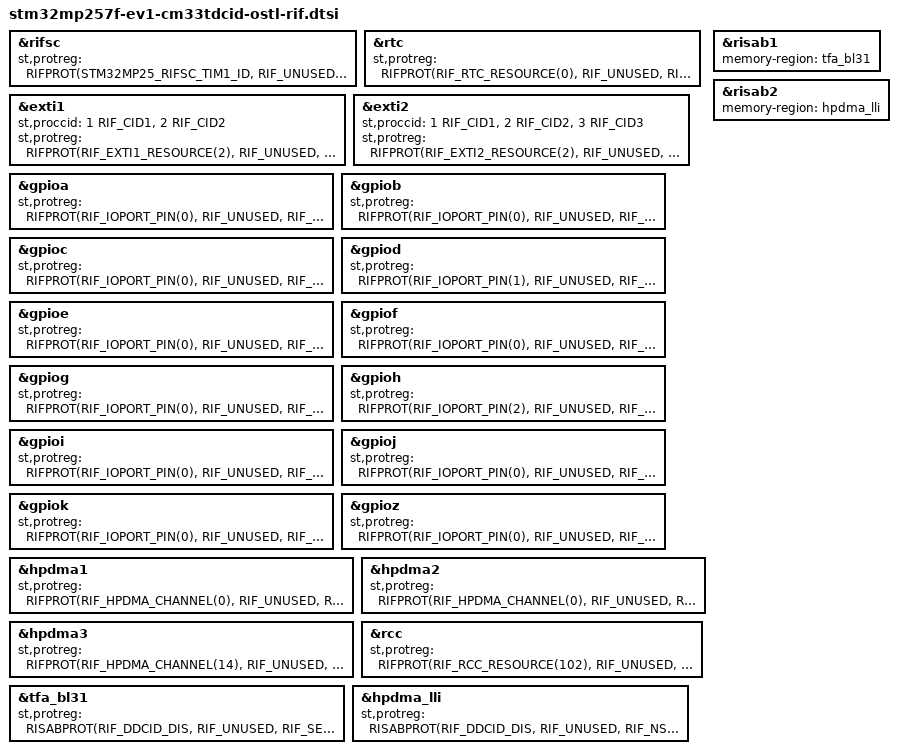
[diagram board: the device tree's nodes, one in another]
// SPDX-License-Identifier: (GPL-2.0-only OR BSD-3-Clause)
/*
 * Copyright (C) STMicroelectronics 2022 - All Rights Reserved
 * Author: Loic Pallardy loic.pallardy@foss.st.com for STMicroelectronics.
 */

/*
 * STM32MP25 RIF device tree configuration
 * Project : ostl-beta-m33td
 * Generated by XLmx tool version 2.2 - 11/21/2023 5:45:09 PM
 */

&rifsc {
	st,protreg = <
		RIFPROT(STM32MP25_RIFSC_TIM1_ID, RIF_UNUSED, RIF_UNLOCK, RIF_NSEC, RIF_NPRIV, RIF_CID1, RIF_SEM_DIS, RIF_CFEN)
		RIFPROT(STM32MP25_RIFSC_TIM3_ID, RIF_UNUSED, RIF_UNLOCK, RIF_NSEC, RIF_NPRIV, RIF_CID1, RIF_SEM_DIS, RIF_CFEN)
		RIFPROT(STM32MP25_RIFSC_TIM4_ID, RIF_UNUSED, RIF_UNLOCK, RIF_NSEC, RIF_NPRIV, RIF_CID1, RIF_SEM_DIS, RIF_CFEN)
		RIFPROT(STM32MP25_RIFSC_TIM5_ID, RIF_UNUSED, RIF_UNLOCK, RIF_NSEC, RIF_NPRIV, RIF_CID1, RIF_SEM_DIS, RIF_CFEN)
		RIFPROT(STM32MP25_RIFSC_TIM7_ID, RIF_UNUSED, RIF_UNLOCK, RIF_NSEC, RIF_NPRIV, RIF_CID1, RIF_SEM_DIS, RIF_CFEN)
		RIFPROT(STM32MP25_RIFSC_TIM8_ID, RIF_UNUSED, RIF_UNLOCK, RIF_NSEC, RIF_NPRIV, RIF_CID1, RIF_SEM_DIS, RIF_CFEN)
		RIFPROT(STM32MP25_RIFSC_TIM10_ID, RIF_UNUSED, RIF_UNLOCK, RIF_NSEC, RIF_NPRIV, RIF_CID1, RIF_SEM_DIS, RIF_CFEN)
		RIFPROT(STM32MP25_RIFSC_TIM11_ID, RIF_UNUSED, RIF_UNLOCK, RIF_NSEC, RIF_NPRIV, RIF_CID1, RIF_SEM_DIS, RIF_CFEN)
		RIFPROT(STM32MP25_RIFSC_TIM12_ID, RIF_UNUSED, RIF_UNLOCK, RIF_NSEC, RIF_NPRIV, RIF_CID1, RIF_SEM_DIS, RIF_CFEN)
		RIFPROT(STM32MP25_RIFSC_TIM13_ID, RIF_UNUSED, RIF_UNLOCK, RIF_NSEC, RIF_NPRIV, RIF_CID1, RIF_SEM_DIS, RIF_CFEN)
		RIFPROT(STM32MP25_RIFSC_TIM14_ID, RIF_UNUSED, RIF_UNLOCK, RIF_NSEC, RIF_NPRIV, RIF_CID1, RIF_SEM_DIS, RIF_CFEN)
		RIFPROT(STM32MP25_RIFSC_TIM15_ID, RIF_UNUSED, RIF_UNLOCK, RIF_NSEC, RIF_NPRIV, RIF_CID1, RIF_SEM_DIS, RIF_CFEN)
		RIFPROT(STM32MP25_RIFSC_TIM16_ID, RIF_UNUSED, RIF_UNLOCK, RIF_NSEC, RIF_NPRIV, RIF_CID1, RIF_SEM_DIS, RIF_CFEN)
		RIFPROT(STM32MP25_RIFSC_TIM17_ID, RIF_UNUSED, RIF_UNLOCK, RIF_NSEC, RIF_NPRIV, RIF_CID1, RIF_SEM_DIS, RIF_CFEN)
		RIFPROT(STM32MP25_RIFSC_TIM20_ID, RIF_UNUSED, RIF_UNLOCK, RIF_NSEC, RIF_NPRIV, RIF_CID1, RIF_SEM_DIS, RIF_CFEN)
		RIFPROT(STM32MP25_RIFSC_LPTIM1_ID, RIF_UNUSED, RIF_UNLOCK, RIF_NSEC, RIF_NPRIV, RIF_CID1, RIF_SEM_DIS, RIF_CFEN)
		RIFPROT(STM32MP25_RIFSC_LPTIM2_ID, RIF_UNUSED, RIF_UNLOCK, RIF_NSEC, RIF_NPRIV, RIF_CID1, RIF_SEM_DIS, RIF_CFEN)
		RIFPROT(STM32MP25_RIFSC_LPTIM3_ID, RIF_UNUSED, RIF_UNLOCK, RIF_NSEC, RIF_NPRIV, RIF_CID1, RIF_SEM_DIS, RIF_CFEN)
		RIFPROT(STM32MP25_RIFSC_LPTIM4_ID, RIF_UNUSED, RIF_UNLOCK, RIF_NSEC, RIF_NPRIV, RIF_CID1, RIF_SEM_DIS, RIF_CFEN)
		RIFPROT(STM32MP25_RIFSC_LPTIM5_ID, RIF_UNUSED, RIF_UNLOCK, RIF_NSEC, RIF_NPRIV, RIF_CID1, RIF_SEM_DIS, RIF_CFEN)
		RIFPROT(STM32MP25_RIFSC_SPI2_ID, RIF_UNUSED, RIF_UNLOCK, RIF_NSEC, RIF_NPRIV, RIF_CID1, RIF_SEM_DIS, RIF_CFEN)
		RIFPROT(STM32MP25_RIFSC_SPI3_ID, RIF_UNUSED, RIF_UNLOCK, RIF_NSEC, RIF_NPRIV, RIF_CID1, RIF_SEM_DIS, RIF_CFEN)
		RIFPROT(STM32MP25_RIFSC_SPI8_ID, RIF_UNUSED, RIF_UNLOCK, RIF_NSEC, RIF_NPRIV, RIF_CID1, RIF_SEM_DIS, RIF_CFEN)
		RIFPROT(STM32MP25_RIFSC_USART2_ID, RIF_UNUSED, RIF_UNLOCK, RIF_NSEC, RIF_NPRIV, RIF_CID1, RIF_SEM_DIS, RIF_CFEN)
		RIFPROT(STM32MP25_RIFSC_USART6_ID, RIF_UNUSED, RIF_UNLOCK, RIF_NSEC, RIF_NPRIV, RIF_CID1, RIF_SEM_DIS, RIF_CFEN)
		RIFPROT(STM32MP25_RIFSC_I2C2_ID, RIF_UNUSED, RIF_UNLOCK, RIF_NSEC, RIF_NPRIV, RIF_CID1, RIF_SEM_DIS, RIF_CFEN)
		RIFPROT(STM32MP25_RIFSC_I2C8_ID, RIF_UNUSED, RIF_UNLOCK, RIF_NSEC, RIF_NPRIV, RIF_CID1, RIF_SEM_DIS, RIF_CFEN)
		RIFPROT(STM32MP25_RIFSC_SAI2_ID, RIF_UNUSED, RIF_UNLOCK, RIF_NSEC, RIF_NPRIV, RIF_CID1, RIF_SEM_DIS, RIF_CFEN)
		RIFPROT(STM32MP25_RIFSC_MDF1_ID, RIF_UNUSED, RIF_UNLOCK, RIF_NSEC, RIF_NPRIV, RIF_CID1, RIF_SEM_DIS, RIF_CFEN)
		RIFPROT(STM32MP25_RIFSC_FDCAN_ID, RIF_UNUSED, RIF_UNLOCK, RIF_NSEC, RIF_NPRIV, RIF_CID1, RIF_SEM_DIS, RIF_CFEN)
		RIFPROT(STM32MP25_RIFSC_HDP_ID, RIF_UNUSED, RIF_UNLOCK, RIF_NSEC, RIF_PRIV, RIF_CID1, RIF_SEM_DIS, RIF_CFEN)
		RIFPROT(STM32MP25_RIFSC_ADC12_ID, RIF_UNUSED, RIF_UNLOCK, RIF_NSEC, RIF_NPRIV, RIF_CID1, RIF_SEM_DIS, RIF_CFEN)
		RIFPROT(STM32MP25_RIFSC_ETH1_ID, RIF_UNUSED, RIF_UNLOCK, RIF_NSEC, RIF_PRIV, RIF_CID1, RIF_SEM_DIS, RIF_CFEN)
		RIFPROT(STM32MP25_RIFSC_ETH2_ID, RIF_UNUSED, RIF_UNLOCK, RIF_NSEC, RIF_NPRIV, RIF_CID1, RIF_SEM_DIS, RIF_CFEN)
		RIFPROT(STM32MP25_RIFSC_ETHSW_DEIP_ID, RIF_UNUSED, RIF_UNLOCK, RIF_NSEC, RIF_PRIV, RIF_CID1, RIF_SEM_DIS, RIF_CFEN)
		RIFPROT(STM32MP25_RIFSC_ETHSW_ACM_MSGBUF_ID, RIF_UNUSED, RIF_UNLOCK, RIF_NSEC, RIF_NPRIV, RIF_CID1, RIF_SEM_DIS, RIF_CFEN)
		RIFPROT(STM32MP25_RIFSC_ETHSW_ACM_CFG_ID, RIF_UNUSED, RIF_UNLOCK, RIF_NSEC, RIF_PRIV, RIF_CID1, RIF_SEM_DIS, RIF_CFEN)
		RIFPROT(STM32MP25_RIFSC_USBH_ID, RIF_UNUSED, RIF_UNLOCK, RIF_NSEC, RIF_PRIV, RIF_CID1, RIF_SEM_DIS, RIF_CFEN)
		RIFPROT(STM32MP25_RIFSC_USB3DR_ID, RIF_UNUSED, RIF_UNLOCK, RIF_NSEC, RIF_PRIV, RIF_CID1, RIF_SEM_DIS, RIF_CFEN)
		RIFPROT(STM32MP25_RIFSC_COMBOPHY_ID, RIF_UNUSED, RIF_UNLOCK, RIF_NSEC, RIF_PRIV, RIF_CID1, RIF_SEM_DIS, RIF_CFEN)
		RIFPROT(STM32MP25_RIFSC_PCIE_ID, RIF_UNUSED, RIF_UNLOCK, RIF_NSEC, RIF_PRIV, RIF_CID1, RIF_SEM_DIS, RIF_CFEN)
		RIFPROT(STM32MP25_RIFSC_SDMMC1_ID, RIF_UNUSED, RIF_UNLOCK, RIF_NSEC, RIF_PRIV, RIF_CID1, RIF_SEM_DIS, RIF_CFEN)
		RIFPROT(STM32MP25_RIFSC_GPU_ID, RIF_UNUSED, RIF_UNLOCK, RIF_NSEC, RIF_PRIV, RIF_CID1, RIF_SEM_DIS, RIF_CFEN)
		RIFPROT(STM32MP25_RIFSC_LTDC_CMN_ID, RIF_UNUSED, RIF_UNLOCK, RIF_NSEC, RIF_PRIV, RIF_CID1, RIF_SEM_DIS, RIF_CFEN)
		RIFPROT(STM32MP25_RIFSC_LTDC_L0L1_ID, RIF_UNUSED, RIF_UNLOCK, RIF_NSEC, RIF_PRIV, RIF_CID1, RIF_SEM_DIS, RIF_CFEN)
		RIFPROT(STM32MP25_RIFSC_DSI_CMN_ID, RIF_UNUSED, RIF_UNLOCK, RIF_NSEC, RIF_PRIV, RIF_CID1, RIF_SEM_DIS, RIF_CFEN)
		RIFPROT(STM32MP25_RIFSC_DSI_TRIG_ID, RIF_UNUSED, RIF_UNLOCK, RIF_NSEC, RIF_PRIV, RIF_CID1, RIF_SEM_DIS, RIF_CFEN)
		RIFPROT(STM32MP25_RIFSC_DSI_RDFIFO_ID, RIF_UNUSED, RIF_UNLOCK, RIF_NSEC, RIF_PRIV, RIF_CID1, RIF_SEM_DIS, RIF_CFEN)
		RIFPROT(STM32MP25_RIFSC_LVDS_ID, RIF_UNUSED, RIF_UNLOCK, RIF_NSEC, RIF_PRIV, RIF_CID1, RIF_SEM_DIS, RIF_CFEN)
		RIFPROT(STM32MP25_RIFSC_CSI_ID, RIF_UNUSED, RIF_UNLOCK, RIF_NSEC, RIF_NPRIV, RIF_CID1, RIF_SEM_DIS, RIF_CFEN)
		RIFPROT(STM32MP25_RIFSC_DCMIPP_ID, RIF_UNUSED, RIF_UNLOCK, RIF_NSEC, RIF_NPRIV, RIF_CID1, RIF_SEM_DIS, RIF_CFEN)
		RIFPROT(STM32MP25_RIFSC_VDEC_ID, RIF_UNUSED, RIF_UNLOCK, RIF_NSEC, RIF_PRIV, RIF_CID1, RIF_SEM_DIS, RIF_CFEN)
		RIFPROT(STM32MP25_RIFSC_VENC_ID, RIF_UNUSED, RIF_UNLOCK, RIF_NSEC, RIF_PRIV, RIF_CID1, RIF_SEM_DIS, RIF_CFEN)
		RIFPROT(STM32MP25_RIFSC_CRYP1_ID, RIF_UNUSED, RIF_LOCK, RIF_NSEC, RIF_PRIV, RIF_CID1, RIF_SEM_DIS, RIF_CFEN)
		RIFPROT(STM32MP25_RIFSC_IWDG2_ID, RIF_UNUSED, RIF_UNLOCK, RIF_NSEC, RIF_PRIV, RIF_CID1, RIF_SEM_DIS, RIF_CFEN)
		RIFPROT(STM32MP25_RIFSC_DTS_ID, RIF_UNUSED, RIF_UNLOCK, RIF_NSEC, RIF_PRIV, RIF_CID1, RIF_SEM_DIS, RIF_CFEN)
		RIFPROT(STM32MP25_RIFSC_GICV2M_ID, RIF_UNUSED, RIF_UNLOCK, RIF_NSEC, RIF_PRIV, RIF_CID1, RIF_SEM_DIS, RIF_CFEN)
	>;
};

&rtc {
	st,protreg = <
		RIFPROT(RIF_RTC_RESOURCE(0), RIF_UNUSED, RIF_UNLOCK, RIF_NSEC, RIF_PRIV, RIF_CID1, RIF_SEM_DIS, RIF_CFEN)
		RIFPROT(RIF_RTC_RESOURCE(3), RIF_UNUSED, RIF_UNLOCK, RIF_NSEC, RIF_PRIV, RIF_CID1, RIF_SEM_DIS, RIF_CFEN)
		RIFPROT(RIF_RTC_RESOURCE(4), RIF_UNUSED, RIF_UNLOCK, RIF_NSEC, RIF_PRIV, RIF_CID1, RIF_SEM_DIS, RIF_CFEN)
		RIFPROT(RIF_RTC_RESOURCE(5), RIF_UNUSED, RIF_UNLOCK, RIF_NSEC, RIF_PRIV, RIF_CID1, RIF_SEM_DIS, RIF_CFEN)
	>;
};

&exti1 {
	st,proccid = <1 RIF_CID1>, <2 RIF_CID2>;
	st,protreg = <
		RIFPROT(RIF_EXTI1_RESOURCE(2), RIF_UNUSED, RIF_UNLOCK, RIF_NSEC, RIF_PRIV, RIF_CID1, RIF_SEM_DIS, RIF_CFEN)
		RIFPROT(RIF_EXTI1_RESOURCE(3), RIF_UNUSED, RIF_UNLOCK, RIF_NSEC, RIF_PRIV, RIF_CID1, RIF_SEM_DIS, RIF_CFEN)
		RIFPROT(RIF_EXTI1_RESOURCE(4), RIF_UNUSED, RIF_UNLOCK, RIF_NSEC, RIF_PRIV, RIF_CID1, RIF_SEM_DIS, RIF_CFEN)
		RIFPROT(RIF_EXTI1_RESOURCE(13), RIF_UNUSED, RIF_UNLOCK, RIF_NSEC, RIF_PRIV, RIF_CID1, RIF_SEM_DIS, RIF_CFEN)
		RIFPROT(RIF_EXTI1_RESOURCE(22), RIF_UNUSED, RIF_UNLOCK, RIF_NSEC, RIF_NPRIV, RIF_CID1, RIF_SEM_DIS, RIF_CFEN)
		RIFPROT(RIF_EXTI1_RESOURCE(27), RIF_UNUSED, RIF_UNLOCK, RIF_NSEC, RIF_NPRIV, RIF_CID1, RIF_SEM_DIS, RIF_CFEN)
		RIFPROT(RIF_EXTI1_RESOURCE(29), RIF_UNUSED, RIF_UNLOCK, RIF_NSEC, RIF_NPRIV, RIF_CID1, RIF_SEM_DIS, RIF_CFEN)
		RIFPROT(RIF_EXTI1_RESOURCE(37), RIF_UNUSED, RIF_UNLOCK, RIF_NSEC, RIF_NPRIV, RIF_CID1, RIF_SEM_DIS, RIF_CFEN)
		RIFPROT(RIF_EXTI1_RESOURCE(38), RIF_UNUSED, RIF_UNLOCK, RIF_NSEC, RIF_NPRIV, RIF_CID1, RIF_SEM_DIS, RIF_CFEN)
		RIFPROT(RIF_EXTI1_RESOURCE(43), RIF_UNUSED, RIF_UNLOCK, RIF_NSEC, RIF_PRIV, RIF_CID1, RIF_SEM_DIS, RIF_CFEN)
		RIFPROT(RIF_EXTI1_RESOURCE(44), RIF_UNUSED, RIF_UNLOCK, RIF_NSEC, RIF_PRIV, RIF_CID1, RIF_SEM_DIS, RIF_CFEN)
		RIFPROT(RIF_EXTI1_RESOURCE(45), RIF_UNUSED, RIF_UNLOCK, RIF_NSEC, RIF_PRIV, RIF_CID1, RIF_SEM_DIS, RIF_CFEN)
		RIFPROT(RIF_EXTI1_RESOURCE(47), RIF_UNUSED, RIF_UNLOCK, RIF_NSEC, RIF_NPRIV, RIF_CID1, RIF_SEM_DIS, RIF_CFEN)
		RIFPROT(RIF_EXTI1_RESOURCE(48), RIF_UNUSED, RIF_UNLOCK, RIF_NSEC, RIF_NPRIV, RIF_CID1, RIF_SEM_DIS, RIF_CFEN)
		RIFPROT(RIF_EXTI1_RESOURCE(52), RIF_UNUSED, RIF_UNLOCK, RIF_NSEC, RIF_PRIV, RIF_CID1, RIF_SEM_DIS, RIF_CFEN)
		RIFPROT(RIF_EXTI1_RESOURCE(53), RIF_UNUSED, RIF_UNLOCK, RIF_NSEC, RIF_PRIV, RIF_CID1, RIF_SEM_DIS, RIF_CFEN)
		RIFPROT(RIF_EXTI1_RESOURCE(59), RIF_UNUSED, RIF_UNLOCK, RIF_NSEC, RIF_NPRIV, RIF_CID1, RIF_SEM_DIS, RIF_CFEN)
		RIFPROT(RIF_EXTI1_RESOURCE(68), RIF_UNUSED, RIF_UNLOCK, RIF_NSEC, RIF_PRIV, RIF_CID1, RIF_SEM_DIS, RIF_CFEN)
		RIFPROT(RIF_EXTI1_RESOURCE(69), RIF_UNUSED, RIF_UNLOCK, RIF_NSEC, RIF_PRIV, RIF_CID1, RIF_SEM_DIS, RIF_CFEN)
		RIFPROT(RIF_EXTI1_RESOURCE(70), RIF_UNUSED, RIF_UNLOCK, RIF_NSEC, RIF_NPRIV, RIF_CID1, RIF_SEM_DIS, RIF_CFEN)
		RIFPROT(RIF_EXTI1_RESOURCE(71), RIF_UNUSED, RIF_UNLOCK, RIF_NSEC, RIF_NPRIV, RIF_CID1, RIF_SEM_DIS, RIF_CFEN)
		RIFPROT(RIF_EXTI1_RESOURCE(72), RIF_UNUSED, RIF_UNLOCK, RIF_NSEC, RIF_PRIV, RIF_CID1, RIF_SEM_DIS, RIF_CFEN)
		RIFPROT(RIF_EXTI1_RESOURCE(77), RIF_UNUSED, RIF_UNLOCK, RIF_NSEC, RIF_NPRIV, RIF_CID1, RIF_SEM_DIS, RIF_CFEN)
		RIFPROT(RIF_EXTI1_RESOURCE(78), RIF_UNUSED, RIF_UNLOCK, RIF_NSEC, RIF_NPRIV, RIF_CID1, RIF_SEM_DIS, RIF_CFEN)
		RIFPROT(RIF_EXTI1_RESOURCE(79), RIF_UNUSED, RIF_UNLOCK, RIF_NSEC, RIF_NPRIV, RIF_CID1, RIF_SEM_DIS, RIF_CFEN)
	>;
};

&exti2 {
	st,proccid = <1 RIF_CID1>, <2 RIF_CID2>, <3 RIF_CID3>;
	st,protreg = <
		RIFPROT(RIF_EXTI2_RESOURCE(2), RIF_UNUSED, RIF_UNLOCK, RIF_NSEC, RIF_PRIV, RIF_CID1, RIF_SEM_DIS, RIF_CFEN)
		RIFPROT(RIF_EXTI2_RESOURCE(16), RIF_UNUSED, RIF_UNLOCK, RIF_NSEC, RIF_NPRIV, RIF_CID1, RIF_SEM_DIS, RIF_CFEN)
		RIFPROT(RIF_EXTI2_RESOURCE(17), RIF_UNUSED, RIF_UNLOCK, RIF_NSEC, RIF_NPRIV, RIF_CID1, RIF_SEM_DIS, RIF_CFEN)
		RIFPROT(RIF_EXTI2_RESOURCE(25), RIF_UNUSED, RIF_UNLOCK, RIF_NSEC, RIF_NPRIV, RIF_CID1, RIF_SEM_DIS, RIF_CFEN)
		RIFPROT(RIF_EXTI2_RESOURCE(27), RIF_UNUSED, RIF_UNLOCK, RIF_NSEC, RIF_NPRIV, RIF_CID1, RIF_SEM_DIS, RIF_CFEN)
		RIFPROT(RIF_EXTI2_RESOURCE(29), RIF_UNUSED, RIF_UNLOCK, RIF_NSEC, RIF_NPRIV, RIF_CID1, RIF_SEM_DIS, RIF_CFEN)
		RIFPROT(RIF_EXTI2_RESOURCE(30), RIF_UNUSED, RIF_UNLOCK, RIF_NSEC, RIF_NPRIV, RIF_CID1, RIF_SEM_DIS, RIF_CFEN)
		RIFPROT(RIF_EXTI2_RESOURCE(31), RIF_UNUSED, RIF_UNLOCK, RIF_NSEC, RIF_NPRIV, RIF_CID1, RIF_SEM_DIS, RIF_CFEN)
		RIFPROT(RIF_EXTI2_RESOURCE(34), RIF_UNUSED, RIF_UNLOCK, RIF_NSEC, RIF_NPRIV, RIF_CID1, RIF_SEM_DIS, RIF_CFEN)
		RIFPROT(RIF_EXTI2_RESOURCE(40), RIF_UNUSED, RIF_UNLOCK, RIF_NSEC, RIF_NPRIV, RIF_CID1, RIF_SEM_DIS, RIF_CFEN)
		RIFPROT(RIF_EXTI2_RESOURCE(53), RIF_UNUSED, RIF_UNLOCK, RIF_NSEC, RIF_PRIV, RIF_CID1, RIF_SEM_DIS, RIF_CFEN)
	>;
};

&gpioa {
	st,protreg = <
		RIFPROT(RIF_IOPORT_PIN(0), RIF_UNUSED, RIF_UNLOCK, RIF_NSEC, RIF_PRIV, RIF_CID1, RIF_SEM_DIS, RIF_CFEN)
		RIFPROT(RIF_IOPORT_PIN(1), RIF_UNUSED, RIF_UNLOCK, RIF_NSEC, RIF_PRIV, RIF_CID1, RIF_SEM_DIS, RIF_CFEN)
		RIFPROT(RIF_IOPORT_PIN(2), RIF_UNUSED, RIF_UNLOCK, RIF_NSEC, RIF_PRIV, RIF_CID1, RIF_SEM_DIS, RIF_CFEN)
		RIFPROT(RIF_IOPORT_PIN(3), RIF_UNUSED, RIF_UNLOCK, RIF_NSEC, RIF_PRIV, RIF_CID1, RIF_SEM_DIS, RIF_CFEN)
		RIFPROT(RIF_IOPORT_PIN(4), RIF_UNUSED, RIF_UNLOCK, RIF_NSEC, RIF_PRIV, RIF_CID1, RIF_SEM_DIS, RIF_CFEN)
		RIFPROT(RIF_IOPORT_PIN(5), RIF_UNUSED, RIF_UNLOCK, RIF_NSEC, RIF_PRIV, RIF_CID1, RIF_SEM_DIS, RIF_CFEN)
		RIFPROT(RIF_IOPORT_PIN(6), RIF_UNUSED, RIF_UNLOCK, RIF_NSEC, RIF_PRIV, RIF_CID1, RIF_SEM_DIS, RIF_CFEN)
		RIFPROT(RIF_IOPORT_PIN(7), RIF_UNUSED, RIF_UNLOCK, RIF_NSEC, RIF_PRIV, RIF_CID1, RIF_SEM_DIS, RIF_CFEN)
		RIFPROT(RIF_IOPORT_PIN(8), RIF_UNUSED, RIF_UNLOCK, RIF_NSEC, RIF_PRIV, RIF_CID1, RIF_SEM_DIS, RIF_CFEN)
		RIFPROT(RIF_IOPORT_PIN(9), RIF_UNUSED, RIF_UNLOCK, RIF_NSEC, RIF_PRIV, RIF_CID1, RIF_SEM_DIS, RIF_CFEN)
		RIFPROT(RIF_IOPORT_PIN(10), RIF_UNUSED, RIF_UNLOCK, RIF_NSEC, RIF_PRIV, RIF_CID1, RIF_SEM_DIS, RIF_CFEN)
		RIFPROT(RIF_IOPORT_PIN(11), RIF_UNUSED, RIF_UNLOCK, RIF_NSEC, RIF_PRIV, RIF_CID1, RIF_SEM_DIS, RIF_CFEN)
		RIFPROT(RIF_IOPORT_PIN(12), RIF_UNUSED, RIF_UNLOCK, RIF_NSEC, RIF_PRIV, RIF_CID1, RIF_SEM_DIS, RIF_CFEN)
		RIFPROT(RIF_IOPORT_PIN(13), RIF_UNUSED, RIF_UNLOCK, RIF_NSEC, RIF_PRIV, RIF_CID1, RIF_SEM_DIS, RIF_CFEN)
		RIFPROT(RIF_IOPORT_PIN(14), RIF_UNUSED, RIF_UNLOCK, RIF_NSEC, RIF_PRIV, RIF_CID1, RIF_SEM_DIS, RIF_CFEN)
		RIFPROT(RIF_IOPORT_PIN(15), RIF_UNUSED, RIF_UNLOCK, RIF_NSEC, RIF_PRIV, RIF_CID1, RIF_SEM_DIS, RIF_CFEN)
	>;
};

&gpiob {
	st,protreg = <
		RIFPROT(RIF_IOPORT_PIN(0), RIF_UNUSED, RIF_UNLOCK, RIF_NSEC, RIF_NPRIV, RIF_CID1, RIF_SEM_DIS, RIF_CFEN)
		RIFPROT(RIF_IOPORT_PIN(1), RIF_UNUSED, RIF_UNLOCK, RIF_NSEC, RIF_NPRIV, RIF_CID1, RIF_SEM_DIS, RIF_CFEN)
		RIFPROT(RIF_IOPORT_PIN(3), RIF_UNUSED, RIF_UNLOCK, RIF_NSEC, RIF_NPRIV, RIF_CID1, RIF_SEM_DIS, RIF_CFEN)
		RIFPROT(RIF_IOPORT_PIN(4), RIF_UNUSED, RIF_UNLOCK, RIF_NSEC, RIF_NPRIV, RIF_CID1, RIF_SEM_DIS, RIF_CFEN)
		RIFPROT(RIF_IOPORT_PIN(5), RIF_UNUSED, RIF_UNLOCK, RIF_NSEC, RIF_NPRIV, RIF_CID1, RIF_SEM_DIS, RIF_CFEN)
		RIFPROT(RIF_IOPORT_PIN(7), RIF_UNUSED, RIF_UNLOCK, RIF_NSEC, RIF_NPRIV, RIF_CID1, RIF_SEM_DIS, RIF_CFEN)
		RIFPROT(RIF_IOPORT_PIN(8), RIF_UNUSED, RIF_UNLOCK, RIF_NSEC, RIF_NPRIV, RIF_CID1, RIF_SEM_DIS, RIF_CFEN)
		RIFPROT(RIF_IOPORT_PIN(9), RIF_UNUSED, RIF_UNLOCK, RIF_NSEC, RIF_NPRIV, RIF_CID1, RIF_SEM_DIS, RIF_CFEN)
		RIFPROT(RIF_IOPORT_PIN(10), RIF_UNUSED, RIF_UNLOCK, RIF_NSEC, RIF_NPRIV, RIF_CID1, RIF_SEM_DIS, RIF_CFEN)
		RIFPROT(RIF_IOPORT_PIN(11), RIF_UNUSED, RIF_UNLOCK, RIF_NSEC, RIF_NPRIV, RIF_CID1, RIF_SEM_DIS, RIF_CFEN)
		RIFPROT(RIF_IOPORT_PIN(15), RIF_UNUSED, RIF_UNLOCK, RIF_NSEC, RIF_PRIV, RIF_CID1, RIF_SEM_DIS, RIF_CFEN)
	>;
};

&gpioc {
	st,protreg = <
		RIFPROT(RIF_IOPORT_PIN(0), RIF_UNUSED, RIF_UNLOCK, RIF_NSEC, RIF_PRIV, RIF_CID1, RIF_SEM_DIS, RIF_CFEN)
		RIFPROT(RIF_IOPORT_PIN(1), RIF_UNUSED, RIF_UNLOCK, RIF_NSEC, RIF_PRIV, RIF_CID1, RIF_SEM_DIS, RIF_CFEN)
		RIFPROT(RIF_IOPORT_PIN(2), RIF_UNUSED, RIF_UNLOCK, RIF_NSEC, RIF_PRIV, RIF_CID1, RIF_SEM_DIS, RIF_CFEN)
		RIFPROT(RIF_IOPORT_PIN(3), RIF_UNUSED, RIF_UNLOCK, RIF_NSEC, RIF_NPRIV, RIF_CID1, RIF_SEM_DIS, RIF_CFEN)
		RIFPROT(RIF_IOPORT_PIN(4), RIF_UNUSED, RIF_UNLOCK, RIF_NSEC, RIF_NPRIV, RIF_CID1, RIF_SEM_DIS, RIF_CFEN)
		RIFPROT(RIF_IOPORT_PIN(5), RIF_UNUSED, RIF_UNLOCK, RIF_NSEC, RIF_NPRIV, RIF_CID1, RIF_SEM_DIS, RIF_CFEN)
		RIFPROT(RIF_IOPORT_PIN(6), RIF_UNUSED, RIF_UNLOCK, RIF_NSEC, RIF_NPRIV, RIF_CID1, RIF_SEM_DIS, RIF_CFEN)
		RIFPROT(RIF_IOPORT_PIN(7), RIF_UNUSED, RIF_UNLOCK, RIF_NSEC, RIF_NPRIV, RIF_CID1, RIF_SEM_DIS, RIF_CFEN)
		RIFPROT(RIF_IOPORT_PIN(8), RIF_UNUSED, RIF_UNLOCK, RIF_NSEC, RIF_NPRIV, RIF_CID1, RIF_SEM_DIS, RIF_CFEN)
		RIFPROT(RIF_IOPORT_PIN(9), RIF_UNUSED, RIF_UNLOCK, RIF_NSEC, RIF_NPRIV, RIF_CID1, RIF_SEM_DIS, RIF_CFEN)
		RIFPROT(RIF_IOPORT_PIN(10), RIF_UNUSED, RIF_UNLOCK, RIF_NSEC, RIF_NPRIV, RIF_CID1, RIF_SEM_DIS, RIF_CFEN)
		RIFPROT(RIF_IOPORT_PIN(11), RIF_UNUSED, RIF_UNLOCK, RIF_NSEC, RIF_NPRIV, RIF_CID1, RIF_SEM_DIS, RIF_CFEN)
		RIFPROT(RIF_IOPORT_PIN(12), RIF_UNUSED, RIF_UNLOCK, RIF_NSEC, RIF_NPRIV, RIF_CID1, RIF_SEM_DIS, RIF_CFEN)
	>;
};

&gpiod {
	st,protreg = <
		RIFPROT(RIF_IOPORT_PIN(1), RIF_UNUSED, RIF_UNLOCK, RIF_NSEC, RIF_NPRIV, RIF_CID1, RIF_SEM_DIS, RIF_CFEN)
		RIFPROT(RIF_IOPORT_PIN(2), RIF_UNUSED, RIF_UNLOCK, RIF_NSEC, RIF_PRIV, RIF_CID1, RIF_SEM_DIS, RIF_CFEN)
		RIFPROT(RIF_IOPORT_PIN(8), RIF_UNUSED, RIF_UNLOCK, RIF_NSEC, RIF_PRIV, RIF_CID1, RIF_SEM_DIS, RIF_CFEN)
		RIFPROT(RIF_IOPORT_PIN(9), RIF_UNUSED, RIF_UNLOCK, RIF_NSEC, RIF_PRIV, RIF_CID1, RIF_SEM_DIS, RIF_CFEN)
		RIFPROT(RIF_IOPORT_PIN(10), RIF_UNUSED, RIF_UNLOCK, RIF_NSEC, RIF_NPRIV, RIF_CID1, RIF_SEM_DIS, RIF_CFEN)
		RIFPROT(RIF_IOPORT_PIN(11), RIF_UNUSED, RIF_UNLOCK, RIF_NSEC, RIF_NPRIV, RIF_CID1, RIF_SEM_DIS, RIF_CFEN)
	>;
};

&gpioe {
	st,protreg = <
		RIFPROT(RIF_IOPORT_PIN(0), RIF_UNUSED, RIF_UNLOCK, RIF_NSEC, RIF_PRIV, RIF_CID1, RIF_SEM_DIS, RIF_CFEN)
		RIFPROT(RIF_IOPORT_PIN(1), RIF_UNUSED, RIF_UNLOCK, RIF_NSEC, RIF_PRIV, RIF_CID1, RIF_SEM_DIS, RIF_CFEN)
		RIFPROT(RIF_IOPORT_PIN(2), RIF_UNUSED, RIF_UNLOCK, RIF_NSEC, RIF_PRIV, RIF_CID1, RIF_SEM_DIS, RIF_CFEN)
		RIFPROT(RIF_IOPORT_PIN(3), RIF_UNUSED, RIF_UNLOCK, RIF_NSEC, RIF_PRIV, RIF_CID1, RIF_SEM_DIS, RIF_CFEN)
		RIFPROT(RIF_IOPORT_PIN(4), RIF_UNUSED, RIF_UNLOCK, RIF_NSEC, RIF_PRIV, RIF_CID1, RIF_SEM_DIS, RIF_CFEN)
		RIFPROT(RIF_IOPORT_PIN(5), RIF_UNUSED, RIF_UNLOCK, RIF_NSEC, RIF_PRIV, RIF_CID1, RIF_SEM_DIS, RIF_CFEN)
		RIFPROT(RIF_IOPORT_PIN(6), RIF_UNUSED, RIF_UNLOCK, RIF_NSEC, RIF_NPRIV, RIF_CID1, RIF_SEM_DIS, RIF_CFEN)
		RIFPROT(RIF_IOPORT_PIN(7), RIF_UNUSED, RIF_UNLOCK, RIF_NSEC, RIF_NPRIV, RIF_CID1, RIF_SEM_DIS, RIF_CFEN)
		RIFPROT(RIF_IOPORT_PIN(8), RIF_UNUSED, RIF_UNLOCK, RIF_NSEC, RIF_NPRIV, RIF_CID1, RIF_SEM_DIS, RIF_CFEN)
		RIFPROT(RIF_IOPORT_PIN(9), RIF_UNUSED, RIF_UNLOCK, RIF_NSEC, RIF_NPRIV, RIF_CID1, RIF_SEM_DIS, RIF_CFEN)
		RIFPROT(RIF_IOPORT_PIN(10), RIF_UNUSED, RIF_UNLOCK, RIF_NSEC, RIF_NPRIV, RIF_CID1, RIF_SEM_DIS, RIF_CFEN)
		RIFPROT(RIF_IOPORT_PIN(11), RIF_UNUSED, RIF_UNLOCK, RIF_NSEC, RIF_NPRIV, RIF_CID1, RIF_SEM_DIS, RIF_CFEN)
		RIFPROT(RIF_IOPORT_PIN(12), RIF_UNUSED, RIF_UNLOCK, RIF_NSEC, RIF_NPRIV, RIF_CID1, RIF_SEM_DIS, RIF_CFEN)
		RIFPROT(RIF_IOPORT_PIN(13), RIF_UNUSED, RIF_UNLOCK, RIF_NSEC, RIF_NPRIV, RIF_CID1, RIF_SEM_DIS, RIF_CFEN)
		RIFPROT(RIF_IOPORT_PIN(14), RIF_UNUSED, RIF_UNLOCK, RIF_NSEC, RIF_NPRIV, RIF_CID1, RIF_SEM_DIS, RIF_CFEN)
		RIFPROT(RIF_IOPORT_PIN(15), RIF_UNUSED, RIF_UNLOCK, RIF_NSEC, RIF_NPRIV, RIF_CID1, RIF_SEM_DIS, RIF_CFEN)
	>;
};

&gpiof {
	st,protreg = <
		RIFPROT(RIF_IOPORT_PIN(0), RIF_UNUSED, RIF_UNLOCK, RIF_NSEC, RIF_PRIV, RIF_CID1, RIF_SEM_DIS, RIF_CFEN)
		RIFPROT(RIF_IOPORT_PIN(1), RIF_UNUSED, RIF_UNLOCK, RIF_NSEC, RIF_PRIV, RIF_CID1, RIF_SEM_DIS, RIF_CFEN)
		RIFPROT(RIF_IOPORT_PIN(2), RIF_UNUSED, RIF_UNLOCK, RIF_NSEC, RIF_PRIV, RIF_CID1, RIF_SEM_DIS, RIF_CFEN)
		RIFPROT(RIF_IOPORT_PIN(3), RIF_UNUSED, RIF_UNLOCK, RIF_NSEC, RIF_PRIV, RIF_CID1, RIF_SEM_DIS, RIF_CFEN)
		RIFPROT(RIF_IOPORT_PIN(4), RIF_UNUSED, RIF_UNLOCK, RIF_NSEC, RIF_NPRIV, RIF_CID1, RIF_SEM_DIS, RIF_CFEN)
		RIFPROT(RIF_IOPORT_PIN(5), RIF_UNUSED, RIF_UNLOCK, RIF_NSEC, RIF_NPRIV, RIF_CID1, RIF_SEM_DIS, RIF_CFEN)
		RIFPROT(RIF_IOPORT_PIN(6), RIF_UNUSED, RIF_UNLOCK, RIF_NSEC, RIF_NPRIV, RIF_CID1, RIF_SEM_DIS, RIF_CFEN)
		RIFPROT(RIF_IOPORT_PIN(7), RIF_UNUSED, RIF_UNLOCK, RIF_NSEC, RIF_NPRIV, RIF_CID1, RIF_SEM_DIS, RIF_CFEN)
		RIFPROT(RIF_IOPORT_PIN(8), RIF_UNUSED, RIF_UNLOCK, RIF_NSEC, RIF_NPRIV, RIF_CID1, RIF_SEM_DIS, RIF_CFEN)
		RIFPROT(RIF_IOPORT_PIN(9), RIF_UNUSED, RIF_UNLOCK, RIF_NSEC, RIF_NPRIV, RIF_CID1, RIF_SEM_DIS, RIF_CFEN)
		RIFPROT(RIF_IOPORT_PIN(11), RIF_UNUSED, RIF_UNLOCK, RIF_NSEC, RIF_NPRIV, RIF_CID1, RIF_SEM_DIS, RIF_CFEN)
		RIFPROT(RIF_IOPORT_PIN(13), RIF_UNUSED, RIF_UNLOCK, RIF_NSEC, RIF_NPRIV, RIF_CID1, RIF_SEM_DIS, RIF_CFEN)
		RIFPROT(RIF_IOPORT_PIN(14), RIF_UNUSED, RIF_UNLOCK, RIF_NSEC, RIF_NPRIV, RIF_CID1, RIF_SEM_DIS, RIF_CFEN)
		RIFPROT(RIF_IOPORT_PIN(15), RIF_UNUSED, RIF_UNLOCK, RIF_NSEC, RIF_NPRIV, RIF_CID1, RIF_SEM_DIS, RIF_CFEN)
	>;
};

&gpiog {
	st,protreg = <
		RIFPROT(RIF_IOPORT_PIN(0), RIF_UNUSED, RIF_UNLOCK, RIF_NSEC, RIF_NPRIV, RIF_CID1, RIF_SEM_DIS, RIF_CFEN)
		RIFPROT(RIF_IOPORT_PIN(3), RIF_UNUSED, RIF_UNLOCK, RIF_NSEC, RIF_PRIV, RIF_CID1, RIF_SEM_DIS, RIF_CFEN)
		RIFPROT(RIF_IOPORT_PIN(4), RIF_UNUSED, RIF_UNLOCK, RIF_NSEC, RIF_PRIV, RIF_CID1, RIF_SEM_DIS, RIF_CFEN)
		RIFPROT(RIF_IOPORT_PIN(5), RIF_UNUSED, RIF_UNLOCK, RIF_NSEC, RIF_NPRIV, RIF_CID1, RIF_SEM_DIS, RIF_CFEN)
		RIFPROT(RIF_IOPORT_PIN(6), RIF_UNUSED, RIF_UNLOCK, RIF_NSEC, RIF_PRIV, RIF_CID1, RIF_SEM_DIS, RIF_CFEN)
		RIFPROT(RIF_IOPORT_PIN(7), RIF_UNUSED, RIF_UNLOCK, RIF_NSEC, RIF_PRIV, RIF_CID1, RIF_SEM_DIS, RIF_CFEN)
		RIFPROT(RIF_IOPORT_PIN(8), RIF_UNUSED, RIF_UNLOCK, RIF_NSEC, RIF_PRIV, RIF_CID1, RIF_SEM_DIS, RIF_CFEN)
		RIFPROT(RIF_IOPORT_PIN(11), RIF_UNUSED, RIF_UNLOCK, RIF_NSEC, RIF_NPRIV, RIF_CID1, RIF_SEM_DIS, RIF_CFEN)
		RIFPROT(RIF_IOPORT_PIN(12), RIF_UNUSED, RIF_UNLOCK, RIF_NSEC, RIF_NPRIV, RIF_CID1, RIF_SEM_DIS, RIF_CFEN)
		RIFPROT(RIF_IOPORT_PIN(14), RIF_UNUSED, RIF_UNLOCK, RIF_NSEC, RIF_PRIV, RIF_CID1, RIF_SEM_DIS, RIF_CFEN)
		RIFPROT(RIF_IOPORT_PIN(15), RIF_UNUSED, RIF_UNLOCK, RIF_NSEC, RIF_PRIV, RIF_CID1, RIF_SEM_DIS, RIF_CFEN)
	>;
};

&gpioh {
	st,protreg = <
		RIFPROT(RIF_IOPORT_PIN(2), RIF_UNUSED, RIF_UNLOCK, RIF_NSEC, RIF_PRIV, RIF_CID1, RIF_SEM_DIS, RIF_CFEN)
		RIFPROT(RIF_IOPORT_PIN(3), RIF_UNUSED, RIF_UNLOCK, RIF_NSEC, RIF_PRIV, RIF_CID1, RIF_SEM_DIS, RIF_CFEN)
		RIFPROT(RIF_IOPORT_PIN(5), RIF_UNUSED, RIF_UNLOCK, RIF_NSEC, RIF_PRIV, RIF_CID1, RIF_SEM_DIS, RIF_CFEN)
		RIFPROT(RIF_IOPORT_PIN(6), RIF_UNUSED, RIF_UNLOCK, RIF_NSEC, RIF_PRIV, RIF_CID1, RIF_SEM_DIS, RIF_CFEN)
		RIFPROT(RIF_IOPORT_PIN(7), RIF_UNUSED, RIF_UNLOCK, RIF_NSEC, RIF_PRIV, RIF_CID1, RIF_SEM_DIS, RIF_CFEN)
		RIFPROT(RIF_IOPORT_PIN(8), RIF_UNUSED, RIF_UNLOCK, RIF_NSEC, RIF_PRIV, RIF_CID1, RIF_SEM_DIS, RIF_CFEN)
		RIFPROT(RIF_IOPORT_PIN(9), RIF_UNUSED, RIF_UNLOCK, RIF_NSEC, RIF_PRIV, RIF_CID1, RIF_SEM_DIS, RIF_CFEN)
		RIFPROT(RIF_IOPORT_PIN(10), RIF_UNUSED, RIF_UNLOCK, RIF_NSEC, RIF_PRIV, RIF_CID1, RIF_SEM_DIS, RIF_CFEN)
		RIFPROT(RIF_IOPORT_PIN(11), RIF_UNUSED, RIF_UNLOCK, RIF_NSEC, RIF_PRIV, RIF_CID1, RIF_SEM_DIS, RIF_CFEN)
		RIFPROT(RIF_IOPORT_PIN(12), RIF_UNUSED, RIF_UNLOCK, RIF_NSEC, RIF_PRIV, RIF_CID1, RIF_SEM_DIS, RIF_CFEN)
		RIFPROT(RIF_IOPORT_PIN(13), RIF_UNUSED, RIF_UNLOCK, RIF_NSEC, RIF_PRIV, RIF_CID1, RIF_SEM_DIS, RIF_CFEN)
	>;
};

&gpioi {
	st,protreg = <
		RIFPROT(RIF_IOPORT_PIN(0), RIF_UNUSED, RIF_UNLOCK, RIF_NSEC, RIF_PRIV, RIF_CID1, RIF_SEM_DIS, RIF_CFEN)
		RIFPROT(RIF_IOPORT_PIN(2), RIF_UNUSED, RIF_UNLOCK, RIF_NSEC, RIF_PRIV, RIF_CID1, RIF_SEM_DIS, RIF_CFEN)
		RIFPROT(RIF_IOPORT_PIN(3), RIF_UNUSED, RIF_UNLOCK, RIF_NSEC, RIF_PRIV, RIF_CID1, RIF_SEM_DIS, RIF_CFEN)
		RIFPROT(RIF_IOPORT_PIN(4), RIF_UNUSED, RIF_UNLOCK, RIF_NSEC, RIF_PRIV, RIF_CID1, RIF_SEM_DIS, RIF_CFEN)
		RIFPROT(RIF_IOPORT_PIN(5), RIF_UNUSED, RIF_UNLOCK, RIF_NSEC, RIF_PRIV, RIF_CID1, RIF_SEM_DIS, RIF_CFEN)
		RIFPROT(RIF_IOPORT_PIN(7), RIF_UNUSED, RIF_UNLOCK, RIF_NSEC, RIF_PRIV, RIF_CID1, RIF_SEM_DIS, RIF_CFEN)
		RIFPROT(RIF_IOPORT_PIN(8), RIF_UNUSED, RIF_UNLOCK, RIF_NSEC, RIF_PRIV, RIF_CID1, RIF_SEM_DIS, RIF_CFEN)
		RIFPROT(RIF_IOPORT_PIN(9), RIF_UNUSED, RIF_UNLOCK, RIF_NSEC, RIF_PRIV, RIF_CID1, RIF_SEM_DIS, RIF_CFEN)
		RIFPROT(RIF_IOPORT_PIN(10), RIF_UNUSED, RIF_UNLOCK, RIF_NSEC, RIF_NPRIV, RIF_CID1, RIF_SEM_DIS, RIF_CFEN)
		RIFPROT(RIF_IOPORT_PIN(12), RIF_UNUSED, RIF_UNLOCK, RIF_NSEC, RIF_NPRIV, RIF_CID1, RIF_SEM_DIS, RIF_CFEN)
		RIFPROT(RIF_IOPORT_PIN(13), RIF_UNUSED, RIF_UNLOCK, RIF_NSEC, RIF_PRIV, RIF_CID1, RIF_SEM_DIS, RIF_CFEN)
		RIFPROT(RIF_IOPORT_PIN(14), RIF_UNUSED, RIF_UNLOCK, RIF_NSEC, RIF_NPRIV, RIF_CID1, RIF_SEM_DIS, RIF_CFEN)
	>;
};

&gpioj {
	st,protreg = <
		RIFPROT(RIF_IOPORT_PIN(0), RIF_UNUSED, RIF_UNLOCK, RIF_NSEC, RIF_PRIV, RIF_CID1, RIF_SEM_DIS, RIF_CFEN)
		RIFPROT(RIF_IOPORT_PIN(1), RIF_UNUSED, RIF_UNLOCK, RIF_NSEC, RIF_PRIV, RIF_CID1, RIF_SEM_DIS, RIF_CFEN)
		RIFPROT(RIF_IOPORT_PIN(2), RIF_UNUSED, RIF_UNLOCK, RIF_NSEC, RIF_NPRIV, RIF_CID1, RIF_SEM_DIS, RIF_CFEN)
		RIFPROT(RIF_IOPORT_PIN(3), RIF_UNUSED, RIF_UNLOCK, RIF_NSEC, RIF_NPRIV, RIF_CID1, RIF_SEM_DIS, RIF_CFEN)
		RIFPROT(RIF_IOPORT_PIN(4), RIF_UNUSED, RIF_UNLOCK, RIF_NSEC, RIF_NPRIV, RIF_CID1, RIF_SEM_DIS, RIF_CFEN)
		RIFPROT(RIF_IOPORT_PIN(5), RIF_UNUSED, RIF_UNLOCK, RIF_NSEC, RIF_NPRIV, RIF_CID1, RIF_SEM_DIS, RIF_CFEN)
		RIFPROT(RIF_IOPORT_PIN(7), RIF_UNUSED, RIF_UNLOCK, RIF_NSEC, RIF_PRIV, RIF_CID1, RIF_SEM_DIS, RIF_CFEN)
		RIFPROT(RIF_IOPORT_PIN(8), RIF_UNUSED, RIF_UNLOCK, RIF_NSEC, RIF_PRIV, RIF_CID1, RIF_SEM_DIS, RIF_CFEN)
		RIFPROT(RIF_IOPORT_PIN(9), RIF_UNUSED, RIF_UNLOCK, RIF_NSEC, RIF_PRIV, RIF_CID1, RIF_SEM_DIS, RIF_CFEN)
		RIFPROT(RIF_IOPORT_PIN(11), RIF_UNUSED, RIF_UNLOCK, RIF_NSEC, RIF_NPRIV, RIF_CID1, RIF_SEM_DIS, RIF_CFEN)
		RIFPROT(RIF_IOPORT_PIN(12), RIF_UNUSED, RIF_UNLOCK, RIF_NSEC, RIF_NPRIV, RIF_CID1, RIF_SEM_DIS, RIF_CFEN)
		RIFPROT(RIF_IOPORT_PIN(13), RIF_UNUSED, RIF_UNLOCK, RIF_NSEC, RIF_PRIV, RIF_CID1, RIF_SEM_DIS, RIF_CFEN)
		RIFPROT(RIF_IOPORT_PIN(14), RIF_UNUSED, RIF_UNLOCK, RIF_NSEC, RIF_NPRIV, RIF_CID1, RIF_SEM_DIS, RIF_CFEN)
		RIFPROT(RIF_IOPORT_PIN(15), RIF_UNUSED, RIF_UNLOCK, RIF_NSEC, RIF_PRIV, RIF_CID1, RIF_SEM_DIS, RIF_CFEN)
	>;
};

&gpiok {
	st,protreg = <
		RIFPROT(RIF_IOPORT_PIN(0), RIF_UNUSED, RIF_UNLOCK, RIF_NSEC, RIF_PRIV, RIF_CID1, RIF_SEM_DIS, RIF_CFEN)
		RIFPROT(RIF_IOPORT_PIN(1), RIF_UNUSED, RIF_UNLOCK, RIF_NSEC, RIF_PRIV, RIF_CID1, RIF_SEM_DIS, RIF_CFEN)
		RIFPROT(RIF_IOPORT_PIN(3), RIF_UNUSED, RIF_UNLOCK, RIF_NSEC, RIF_PRIV, RIF_CID1, RIF_SEM_DIS, RIF_CFEN)
		RIFPROT(RIF_IOPORT_PIN(7), RIF_UNUSED, RIF_UNLOCK, RIF_NSEC, RIF_PRIV, RIF_CID1, RIF_SEM_DIS, RIF_CFEN)
	>;
};

&gpioz {
	st,protreg = <
		RIFPROT(RIF_IOPORT_PIN(0), RIF_UNUSED, RIF_UNLOCK, RIF_NSEC, RIF_NPRIV, RIF_CID1, RIF_SEM_DIS, RIF_CFEN)
		RIFPROT(RIF_IOPORT_PIN(1), RIF_UNUSED, RIF_UNLOCK, RIF_NSEC, RIF_NPRIV, RIF_CID1, RIF_SEM_DIS, RIF_CFEN)
		RIFPROT(RIF_IOPORT_PIN(2), RIF_UNUSED, RIF_UNLOCK, RIF_NSEC, RIF_NPRIV, RIF_CID1, RIF_SEM_DIS, RIF_CFEN)
		RIFPROT(RIF_IOPORT_PIN(3), RIF_UNUSED, RIF_UNLOCK, RIF_NSEC, RIF_NPRIV, RIF_CID1, RIF_SEM_DIS, RIF_CFEN)
		RIFPROT(RIF_IOPORT_PIN(4), RIF_UNUSED, RIF_UNLOCK, RIF_NSEC, RIF_NPRIV, RIF_CID1, RIF_SEM_DIS, RIF_CFEN)
		RIFPROT(RIF_IOPORT_PIN(5), RIF_UNUSED, RIF_UNLOCK, RIF_NSEC, RIF_PRIV, RIF_CID1, RIF_SEM_DIS, RIF_CFEN)
		RIFPROT(RIF_IOPORT_PIN(6), RIF_UNUSED, RIF_UNLOCK, RIF_NSEC, RIF_NPRIV, RIF_CID1, RIF_SEM_DIS, RIF_CFEN)
		RIFPROT(RIF_IOPORT_PIN(9), RIF_UNUSED, RIF_UNLOCK, RIF_NSEC, RIF_PRIV, RIF_CID1, RIF_SEM_DIS, RIF_CFEN)
	>;
};

&hpdma1 {
	st,protreg = <
		RIFPROT(RIF_HPDMA_CHANNEL(0), RIF_UNUSED, RIF_UNLOCK, RIF_NSEC, RIF_PRIV, RIF_CID1, RIF_SEM_DIS, RIF_CFEN)
		RIFPROT(RIF_HPDMA_CHANNEL(1), RIF_UNUSED, RIF_UNLOCK, RIF_NSEC, RIF_PRIV, RIF_CID1, RIF_SEM_DIS, RIF_CFEN)
		RIFPROT(RIF_HPDMA_CHANNEL(2), RIF_UNUSED, RIF_UNLOCK, RIF_NSEC, RIF_PRIV, RIF_CID1, RIF_SEM_DIS, RIF_CFEN)
		RIFPROT(RIF_HPDMA_CHANNEL(3), RIF_UNUSED, RIF_UNLOCK, RIF_NSEC, RIF_PRIV, RIF_CID1, RIF_SEM_DIS, RIF_CFEN)
		RIFPROT(RIF_HPDMA_CHANNEL(4), RIF_UNUSED, RIF_UNLOCK, RIF_NSEC, RIF_PRIV, RIF_CID1, RIF_SEM_DIS, RIF_CFEN)
		RIFPROT(RIF_HPDMA_CHANNEL(5), RIF_UNUSED, RIF_UNLOCK, RIF_NSEC, RIF_PRIV, RIF_CID1, RIF_SEM_DIS, RIF_CFEN)
		RIFPROT(RIF_HPDMA_CHANNEL(6), RIF_UNUSED, RIF_UNLOCK, RIF_NSEC, RIF_PRIV, RIF_CID1, RIF_SEM_DIS, RIF_CFEN)
		RIFPROT(RIF_HPDMA_CHANNEL(7), RIF_UNUSED, RIF_UNLOCK, RIF_NSEC, RIF_PRIV, RIF_CID1, RIF_SEM_DIS, RIF_CFEN)
		RIFPROT(RIF_HPDMA_CHANNEL(8), RIF_UNUSED, RIF_UNLOCK, RIF_NSEC, RIF_PRIV, RIF_CID1, RIF_SEM_DIS, RIF_CFEN)
		RIFPROT(RIF_HPDMA_CHANNEL(9), RIF_UNUSED, RIF_UNLOCK, RIF_NSEC, RIF_PRIV, RIF_CID1, RIF_SEM_DIS, RIF_CFEN)
		RIFPROT(RIF_HPDMA_CHANNEL(10), RIF_UNUSED, RIF_UNLOCK, RIF_NSEC, RIF_PRIV, RIF_CID1, RIF_SEM_DIS, RIF_CFEN)
		RIFPROT(RIF_HPDMA_CHANNEL(11), RIF_UNUSED, RIF_UNLOCK, RIF_NSEC, RIF_PRIV, RIF_CID1, RIF_SEM_DIS, RIF_CFEN)
		RIFPROT(RIF_HPDMA_CHANNEL(12), RIF_UNUSED, RIF_UNLOCK, RIF_NSEC, RIF_PRIV, RIF_CID1, RIF_SEM_DIS, RIF_CFEN)
		RIFPROT(RIF_HPDMA_CHANNEL(13), RIF_UNUSED, RIF_UNLOCK, RIF_NSEC, RIF_PRIV, RIF_CID1, RIF_SEM_DIS, RIF_CFEN)
		RIFPROT(RIF_HPDMA_CHANNEL(14), RIF_UNUSED, RIF_UNLOCK, RIF_NSEC, RIF_PRIV, RIF_CID1, RIF_SEM_DIS, RIF_CFEN)
		RIFPROT(RIF_HPDMA_CHANNEL(15), RIF_UNUSED, RIF_UNLOCK, RIF_NSEC, RIF_PRIV, RIF_CID1, RIF_SEM_DIS, RIF_CFEN)
	>;
};

&hpdma2 {
	st,protreg = <
		RIFPROT(RIF_HPDMA_CHANNEL(0), RIF_UNUSED, RIF_UNLOCK, RIF_NSEC, RIF_PRIV, RIF_CID1, RIF_SEM_DIS, RIF_CFEN)
		RIFPROT(RIF_HPDMA_CHANNEL(1), RIF_UNUSED, RIF_UNLOCK, RIF_NSEC, RIF_PRIV, RIF_CID1, RIF_SEM_DIS, RIF_CFEN)
		RIFPROT(RIF_HPDMA_CHANNEL(2), RIF_UNUSED, RIF_UNLOCK, RIF_NSEC, RIF_PRIV, RIF_CID1, RIF_SEM_DIS, RIF_CFEN)
		RIFPROT(RIF_HPDMA_CHANNEL(3), RIF_UNUSED, RIF_UNLOCK, RIF_NSEC, RIF_PRIV, RIF_CID1, RIF_SEM_DIS, RIF_CFEN)
		RIFPROT(RIF_HPDMA_CHANNEL(4), RIF_UNUSED, RIF_UNLOCK, RIF_NSEC, RIF_PRIV, RIF_CID1, RIF_SEM_DIS, RIF_CFEN)
		RIFPROT(RIF_HPDMA_CHANNEL(5), RIF_UNUSED, RIF_UNLOCK, RIF_NSEC, RIF_PRIV, RIF_CID1, RIF_SEM_DIS, RIF_CFEN)
		RIFPROT(RIF_HPDMA_CHANNEL(6), RIF_UNUSED, RIF_UNLOCK, RIF_NSEC, RIF_PRIV, RIF_CID1, RIF_SEM_DIS, RIF_CFEN)
		RIFPROT(RIF_HPDMA_CHANNEL(7), RIF_UNUSED, RIF_UNLOCK, RIF_NSEC, RIF_PRIV, RIF_CID1, RIF_SEM_DIS, RIF_CFEN)
		RIFPROT(RIF_HPDMA_CHANNEL(8), RIF_UNUSED, RIF_UNLOCK, RIF_NSEC, RIF_PRIV, RIF_CID1, RIF_SEM_DIS, RIF_CFEN)
		RIFPROT(RIF_HPDMA_CHANNEL(9), RIF_UNUSED, RIF_UNLOCK, RIF_NSEC, RIF_PRIV, RIF_CID1, RIF_SEM_DIS, RIF_CFEN)
		RIFPROT(RIF_HPDMA_CHANNEL(10), RIF_UNUSED, RIF_UNLOCK, RIF_NSEC, RIF_PRIV, RIF_CID1, RIF_SEM_DIS, RIF_CFEN)
		RIFPROT(RIF_HPDMA_CHANNEL(11), RIF_UNUSED, RIF_UNLOCK, RIF_NSEC, RIF_PRIV, RIF_CID1, RIF_SEM_DIS, RIF_CFEN)
		RIFPROT(RIF_HPDMA_CHANNEL(12), RIF_UNUSED, RIF_UNLOCK, RIF_NSEC, RIF_PRIV, RIF_CID1, RIF_SEM_DIS, RIF_CFEN)
		RIFPROT(RIF_HPDMA_CHANNEL(13), RIF_UNUSED, RIF_UNLOCK, RIF_NSEC, RIF_PRIV, RIF_CID1, RIF_SEM_DIS, RIF_CFEN)
		RIFPROT(RIF_HPDMA_CHANNEL(14), RIF_UNUSED, RIF_UNLOCK, RIF_NSEC, RIF_PRIV, RIF_CID1, RIF_SEM_DIS, RIF_CFEN)
		RIFPROT(RIF_HPDMA_CHANNEL(15), RIF_UNUSED, RIF_UNLOCK, RIF_NSEC, RIF_PRIV, RIF_CID1, RIF_SEM_DIS, RIF_CFEN)
	>;
};

&hpdma3 {
	st,protreg = <
		RIFPROT(RIF_HPDMA_CHANNEL(14), RIF_UNUSED, RIF_UNLOCK, RIF_NSEC, RIF_PRIV, RIF_CID1, RIF_SEM_DIS, RIF_CFEN)
		RIFPROT(RIF_HPDMA_CHANNEL(15), RIF_UNUSED, RIF_UNLOCK, RIF_NSEC, RIF_PRIV, RIF_CID1, RIF_SEM_DIS, RIF_CFEN)
	>;
};

&rcc {
	st,protreg = <
		RIFPROT(RIF_RCC_RESOURCE(102), RIF_UNUSED, RIF_UNLOCK, RIF_NSEC, RIF_PRIV, RIF_CID1, RIF_SEM_DIS, RIF_CFEN)
	>;
};

&tfa_bl31 {
	st,protreg = <RISABPROT(RIF_DDCID_DIS, RIF_UNUSED, RIF_SEC, RIF_UNUSED, RIF_CFEN, RIF_CID1_BF, RIF_CID1_BF, RIF_CID1_BF)>;
};

&hpdma_lli {
	st,protreg = <RISABPROT(RIF_DDCID_DIS, RIF_UNUSED, RIF_NSEC, RIF_UNUSED, RIF_CFEN, RIF_CID1_BF, RIF_CID1_BF, RIF_CID1_BF)>;
};

&risab1 {
	memory-region = <&tfa_bl31>;
};

&risab2 {
	memory-region = <&hpdma_lli>;
};

